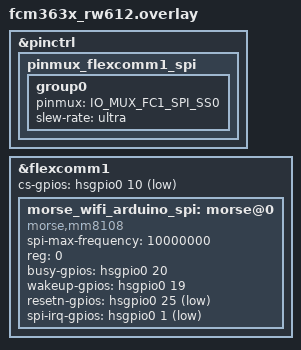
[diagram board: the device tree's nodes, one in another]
&pinctrl {
    status = "okay";
    pinmux_flexcomm1_spi: pinmux_flexcomm1_spi {
        group0 {
            pinmux = <IO_MUX_FC1_SPI_SS0>;
            slew-rate = "ultra";
        };
    };
};

&flexcomm1 {
    status ="okay";
    cs-gpios = <&hsgpio0 10 GPIO_ACTIVE_LOW>;
    
    morse_wifi_arduino_spi: morse@0 {
        status ="okay";
        compatible = "morse,mm8108";
        spi-max-frequency = <10000000>;
        reg = <0>;
        
        /* NOTE: these are the sideband pins of the ORIGINAL wiring, and they are
         * wrong for the Badge_01.00.00 revision, where IRQ/RESET/WAKE/BUSY moved
         * to GPIO44/45/46/47 (hsgpio1 pins 12/13/14/15). Do not "fix" them here:
         * this shield is shared with the main app, whose overlay still uses
         * GPIO44 as the MAX17260 interrupt and GPIO46/47 as LEDs, and any edit in
         * this module is lost on the next `west update`. The production test
         * overrides them from app/1Badge/prod_test/boards/fcm363x.overlay, which
         * is applied after shields. */
        busy-gpios = <&hsgpio0 20 GPIO_ACTIVE_HIGH>;
        wakeup-gpios = <&hsgpio0 19 GPIO_ACTIVE_HIGH>;
        resetn-gpios = <&hsgpio0 25 GPIO_ACTIVE_LOW>;
        spi-irq-gpios = <&hsgpio0 1 GPIO_ACTIVE_LOW>;
    };
};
